AUTOSAR XML (schema 4-2-2)
package /System
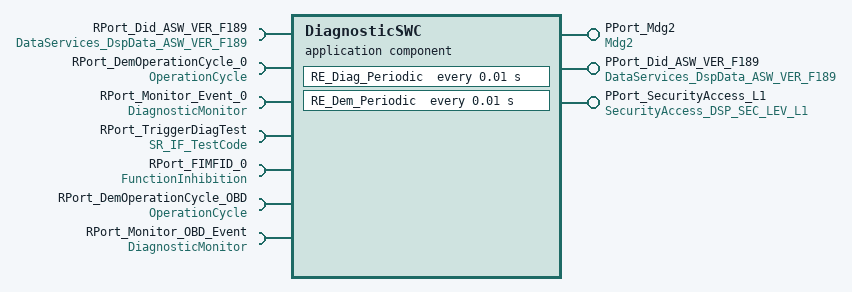
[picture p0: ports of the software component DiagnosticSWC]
  application sw component type DiagnosticSWC
    provide port PPort_Mdg2: provided-interface=Mdg2
    provide port PPort_Did_ASW_VER_F189: provided-interface=DataServices_DspData_ASW_VER_F189
    require port RPort_Did_ASW_VER_F189: required-interface=DataServices_DspData_ASW_VER_F189
    provide port PPort_SecurityAccess_L1: provided-interface=SecurityAccess_DSP_SEC_LEV_L1
    6 x require port:
      RPort_DemOperationCycle_0: required-interface=OperationCycle
      RPort_Monitor_Event_0: required-interface=DiagnosticMonitor
      RPort_TriggerDiagTest: required-interface=SR_IF_TestCode
      RPort_FIMFID_0: required-interface=FunctionInhibition
      RPort_DemOperationCycle_OBD: required-interface=OperationCycle
      RPort_Monitor_OBD_Event: required-interface=DiagnosticMonitor
    behavior InternalBehavior: data-type-mapping=[DataTypeMappingSet_ASW, DTS_Mdg2]
      timing event TE_Diag_Period: start-on-event=RE_Diag_Periodic, period=0.01
      operation invoked event OIE_DSP_SEC_LEV_L1_GS: start-on-event=Swc_DSP_SEC_LEV_L1_GS, operation=PPort_SecurityAccess_L1.GetSeed
      operation invoked event OIE_DSP_SEC_LEV_L1_CK: start-on-event=Swc_DSP_SEC_LEV_L1_CK, operation=PPort_SecurityAccess_L1.CompareKey
      timing event TE_Dem_Period: start-on-event=RE_Dem_Periodic, period=0.01
      4 x runnable:
        RE_Diag_Periodic
          data-receive-point-by-arguments:
            access DRPA_Data_0: accessed-variable=RPort_Did_ASW_VER_F189.Data
          data-send-points:
            access DSP_Data_0: accessed-variable=PPort_Did_ASW_VER_F189.Data
        Swc_DSP_SEC_LEV_L1_CK: symbol=Swc_DSP_SEC_LEV_L1_CK_func
        Swc_DSP_SEC_LEV_L1_GS: symbol=Swc_DSP_SEC_LEV_L1_GS_func
        RE_Dem_Periodic
          data-read-access:
            access DRA_TestCode_0: accessed-variable=RPort_TriggerDiagTest.TestCode
          11 x sync call:
            SynchronousServerCallPoint_0: operation=RPort_DemOperationCycle_0.SetOperationCycleState
            SynchronousServerCallPoint_1: operation=RPort_DemOperationCycle_0.GetOperationCycleState
            SynchronousServerCallPoint_2: operation=RPort_DemOperationCycle_0.GetCycleQualified
            SynchronousServerCallPoint_3: operation=RPort_DemOperationCycle_0.SetCycleQualified
            SynchronousServerCallPoint_4: operation=RPort_Monitor_Event_0.SetEventStatus
            SynchronousServerCallPoint_5: operation=RPort_FIMFID_0.GetFunctionPermission
            SynchronousServerCallPoint_6: operation=RPort_Monitor_OBD_Event.SetEventStatus
            SynchronousServerCallPoint_7: operation=RPort_DemOperationCycle_OBD.SetOperationCycleState
            SynchronousServerCallPoint_8: operation=RPort_DemOperationCycle_OBD.GetOperationCycleState
            SynchronousServerCallPoint_9: operation=RPort_DemOperationCycle_OBD.GetCycleQualified
            SynchronousServerCallPoint_10: operation=RPort_DemOperationCycle_OBD.SetCycleQualified
